AUTOSAR XML (schema 00049)
package /Application/Executable
  executable IVI_MonitoringApp: category=APPLICATION_LEVEL, logging-behavior=USES-LOGGING, reporting-behavior=REPORTS-EXECUTION-STATE, version=1.0.0
    root sw component prototype IVI: application-type=IVI_MonitoringApp
package /Application/Manifest
  service instance to port prototype mapping IVI_MonitoringApp_IVI_PPortStateManager: port-prototype=IVI.PPortStateManager, service-instance=IVI_MonitoringApp_Provider_StateManager
  service instance to port prototype mapping IVI_MonitoringApp_IVI_RPortMonitoringManagement: port-prototype=IVI.RPortMonitoringManagement, service-instance=IVI_MonitoringApp_Consumer_MonitoringManagement
package /Application/Process
  process IVI_MonitoringApp: executable=IVI_MonitoringApp, state-dependent-startup-config{function-group-state=MachineFG.Startup, resource-group=DefaultResourceGroup, startup-config=IVI_MonitoringApp}
    process state machine IVI_MonitoringApp: type=ProcessState
package /Application/StartupConfig
  startup config set EEVP_IVI_StartupConfig
    startup config IVI_MonitoringApp: scheduling-policy=SCHED_OTHER, scheduling-priority=0, timeout={enter-timeout-value=5.0, exit-timeout-value=2.0}
package /Application/SwComponent
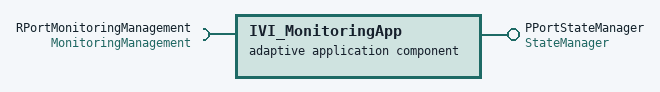
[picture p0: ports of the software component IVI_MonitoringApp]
  adaptive application sw component type IVI_MonitoringApp
    provide port PPortStateManager: provided-interface=StateManager
    require port RPortMonitoringManagement: required-interface=MonitoringManagement
